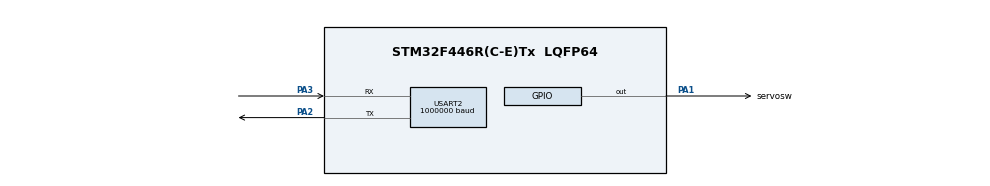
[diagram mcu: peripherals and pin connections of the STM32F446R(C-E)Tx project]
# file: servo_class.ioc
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Mcu.Family=STM32F4
Mcu.Name=STM32F446R(C-E)Tx
Mcu.Package=LQFP64
NVIC.PriorityGroup=NVIC_PRIORITYGROUP_4
PA1.GPIO_Label=servosw
PA1.Signal=GPIO_Output
PA2.Mode=Asynchronous
PA2.Signal=USART2_TX
PA3.Mode=Asynchronous
PA3.Signal=USART2_RX
ProjectManager.HeapSize=0x200
ProjectManager.StackSize=0x400
ProjectManager.TargetToolchain=STM32CubeIDE
RCC.CortexFreq_Value=16000000
RCC.USBFreq_Value=96000000
RCC.VCOOutputFreq_Value=192000000
USART2.BaudRate=1000000
USART2.VirtualMode=VM_ASYNC
board=custom

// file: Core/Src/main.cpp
/* USER CODE BEGIN Header */
/**
  ******************************************************************************
  * @file           : main.c
  * @brief          : Main program body
  ******************************************************************************
  * @attention
  *
  * Copyright (c) 2024 STMicroelectronics.
  * All rights reserved.
  *
  * This software is licensed under terms that can be found in the LICENSE file
  * in the root directory of this software component.
  * If no LICENSE file comes with this software, it is provided AS-IS.
  *
  ******************************************************************************
  */
/* USER CODE END Header */

/* USER CODE BEGIN Includes */
#include "servo.h"

/* USER CODE END Includes */

UART_HandleTypeDef huart2;

/* USER CODE BEGIN PV */
uint8_t status = 0;
uint16_t degree_position = 0;
STS_SERVO servo0(0, &huart2);
STS_SERVO servo1(1, &huart2);
STS_SERVO servo2(2, &huart2);
STS_SERVO servo3(3, &huart2);

/* USER CODE END PV */

void SystemClock_Config(void);
static void MX_GPIO_Init(void);
static void MX_USART2_UART_Init(void);

int main(void)
{

  /* MCU Configuration--------------------------------------------------------*/

  /* Reset of all peripherals, Initializes the Flash interface and the Systick. */
  HAL_Init();

  /* Configure the system clock */
  SystemClock_Config();

  /* Initialize all configured peripherals */
  MX_GPIO_Init();
  MX_USART2_UART_Init();
  /* USER CODE BEGIN 2 */
  HAL_GPIO_WritePin(servosw_GPIO_Port, servosw_Pin, GPIO_PIN_SET);

  /* USER CODE END 2 */

  /* Infinite loop */
  while (1)
  {

    /* USER CODE BEGIN 3 */
	  if(degree_position <= 0){
		  status = 0;
	  	  }
	  if(degree_position >= 360){
		  status = 1;
	  }
	  if(status == 0){
		  degree_position += 3;
	  }else{
		  degree_position -= 3;
	  }
	  servo0.exe_servo(degree_position);
	  servo1.exe_servo(degree_position / 2 + 90);
	  servo2.exe_servo(degree_position);
	  servo3.exe_servo(degree_position / 4 + 100);

  }
  /* USER CODE END 3 */
}

void SystemClock_Config(void)
{
  RCC_OscInitTypeDef RCC_OscInitStruct = {0};
  RCC_ClkInitTypeDef RCC_ClkInitStruct = {0};

  /** Configure the main internal regulator output voltage
  */
  __HAL_RCC_PWR_CLK_ENABLE();
  __HAL_PWR_VOLTAGESCALING_CONFIG(PWR_REGULATOR_VOLTAGE_SCALE3);

  /** Initializes the RCC Oscillators according to the specified parameters
  * in the RCC_OscInitTypeDef structure.
  */
  RCC_OscInitStruct.OscillatorType = RCC_OSCILLATORTYPE_HSI;
  RCC_OscInitStruct.HSIState = RCC_HSI_ON;
  RCC_OscInitStruct.HSICalibrationValue = RCC_HSICALIBRATION_DEFAULT;
  RCC_OscInitStruct.PLL.PLLState = RCC_PLL_NONE;
  if (HAL_RCC_OscConfig(&RCC_OscInitStruct) != HAL_OK)
  {
    Error_Handler();
  }

  /** Initializes the CPU, AHB and APB buses clocks
  */
  RCC_ClkInitStruct.ClockType = RCC_CLOCKTYPE_HCLK|RCC_CLOCKTYPE_SYSCLK
                              |RCC_CLOCKTYPE_PCLK1|RCC_CLOCKTYPE_PCLK2;
  RCC_ClkInitStruct.SYSCLKSource = RCC_SYSCLKSOURCE_HSI;
  RCC_ClkInitStruct.AHBCLKDivider = RCC_SYSCLK_DIV1;
  RCC_ClkInitStruct.APB1CLKDivider = RCC_HCLK_DIV1;
  RCC_ClkInitStruct.APB2CLKDivider = RCC_HCLK_DIV1;

  if (HAL_RCC_ClockConfig(&RCC_ClkInitStruct, FLASH_LATENCY_0) != HAL_OK)
  {
    Error_Handler();
  }
}

static void MX_USART2_UART_Init(void)
{

  huart2.Instance = USART2;
  huart2.Init.BaudRate = 1000000;
  huart2.Init.WordLength = UART_WORDLENGTH_8B;
  huart2.Init.StopBits = UART_STOPBITS_1;
  huart2.Init.Parity = UART_PARITY_NONE;
  huart2.Init.Mode = UART_MODE_TX_RX;
  huart2.Init.HwFlowCtl = UART_HWCONTROL_NONE;
  huart2.Init.OverSampling = UART_OVERSAMPLING_16;
  if (HAL_UART_Init(&huart2) != HAL_OK)
  {
    Error_Handler();
  }

}

static void MX_GPIO_Init(void)
{
  GPIO_InitTypeDef GPIO_InitStruct = {0};

  /* GPIO Ports Clock Enable */
  __HAL_RCC_GPIOA_CLK_ENABLE();

  /*Configure GPIO pin Output Level */
  HAL_GPIO_WritePin(servosw_GPIO_Port, servosw_Pin, GPIO_PIN_RESET);

  /*Configure GPIO pin : servosw_Pin */
  GPIO_InitStruct.Pin = servosw_Pin;
  GPIO_InitStruct.Mode = GPIO_MODE_OUTPUT_PP;
  GPIO_InitStruct.Pull = GPIO_NOPULL;
  GPIO_InitStruct.Speed = GPIO_SPEED_FREQ_LOW;
  HAL_GPIO_Init(servosw_GPIO_Port, &GPIO_InitStruct);

}

void Error_Handler(void)
{
  __disable_irq();
  while (1)
  {
  }
}
